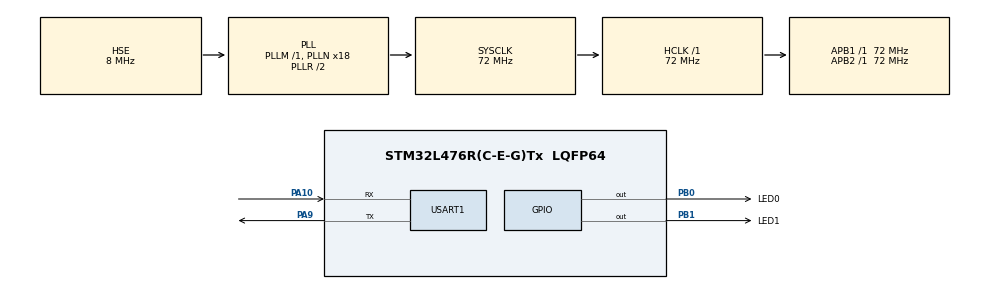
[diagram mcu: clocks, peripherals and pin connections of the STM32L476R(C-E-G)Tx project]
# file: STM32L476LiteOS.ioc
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Mcu.Family=STM32L4
Mcu.Name=STM32L476R(C-E-G)Tx
Mcu.Package=LQFP64
NVIC.PriorityGroup=NVIC_PRIORITYGROUP_4
PA10.Mode=Asynchronous
PA10.Signal=USART1_RX
PA9.Mode=Asynchronous
PA9.Signal=USART1_TX
PB0.GPIO_Label=LED0
PB0.Signal=GPIO_Output
PB1.GPIO_Label=LED1
PB1.Signal=GPIO_Output
PH0-OSC_IN\ (PH0).Mode=HSE-External-Oscillator
PH0-OSC_IN\ (PH0).Signal=RCC_OSC_IN
PH1-OSC_OUT\ (PH1).Mode=HSE-External-Oscillator
PH1-OSC_OUT\ (PH1).Signal=RCC_OSC_OUT
ProjectManager.HeapSize=0x3000
ProjectManager.StackSize=0x400
ProjectManager.TargetToolchain=MDK-ARM V5
RCC.ADCFreq_Value=32000000
RCC.AHBFreq_Value=72000000
RCC.APB1Freq_Value=72000000
RCC.APB1TimFreq_Value=72000000
RCC.APB2Freq_Value=72000000
RCC.APB2TimFreq_Value=72000000
RCC.CortexFreq_Value=72000000
RCC.HCLKFreq_Value=72000000
RCC.HSE_VALUE=8000000
RCC.HSI_VALUE=16000000
RCC.LSE_VALUE=32768
RCC.MSI_VALUE=4000000
RCC.PLLN=18
RCC.PLLSourceVirtual=RCC_PLLSOURCE_HSE
RCC.SYSCLKFreq_VALUE=72000000
RCC.SYSCLKSource=RCC_SYSCLKSOURCE_PLLCLK
RCC.USBFreq_Value=32000000
RCC.VCOOutputFreq_Value=144000000
USART1.VirtualMode-Asynchronous=VM_ASYNC
board=custom

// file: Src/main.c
/* USER CODE BEGIN Header */
/**
  ******************************************************************************
  * @file           : main.c
  * @brief          : Main program body
  ******************************************************************************
  ** This notice applies to any and all portions of this file
  * that are not between comment pairs USER CODE BEGIN and
  * USER CODE END. Other portions of this file, whether
  * inserted by the user or by software development tools
  * are owned by their respective copyright owners.
  *
  * COPYRIGHT(c) 2019 STMicroelectronics
  *
  * Redistribution and use in source and binary forms, with or without modification,
  * are permitted provided that the following conditions are met:
  *   1. Redistributions of source code must retain the above copyright notice,
  *      this list of conditions and the following disclaimer.
  *   2. Redistributions in binary form must reproduce the above copyright notice,
  *      this list of conditions and the following disclaimer in the documentation
  *      and/or other materials provided with the distribution.
  *   3. Neither the name of STMicroelectronics nor the names of its contributors
  *      may be used to endorse or promote products derived from this software
  *      without specific prior written permission.
  *
  * THIS SOFTWARE IS PROVIDED BY THE COPYRIGHT HOLDERS AND CONTRIBUTORS "AS IS"
  * AND ANY EXPRESS OR IMPLIED WARRANTIES, INCLUDING, BUT NOT LIMITED TO, THE
  * IMPLIED WARRANTIES OF MERCHANTABILITY AND FITNESS FOR A PARTICULAR PURPOSE ARE
  * DISCLAIMED. IN NO EVENT SHALL THE COPYRIGHT HOLDER OR CONTRIBUTORS BE LIABLE
  * FOR ANY DIRECT, INDIRECT, INCIDENTAL, SPECIAL, EXEMPLARY, OR CONSEQUENTIAL
  * DAMAGES (INCLUDING, BUT NOT LIMITED TO, PROCUREMENT OF SUBSTITUTE GOODS OR
  * SERVICES; LOSS OF USE, DATA, OR PROFITS; OR BUSINESS INTERRUPTION) HOWEVER
  * CAUSED AND ON ANY THEORY OF LIABILITY, WHETHER IN CONTRACT, STRICT LIABILITY,
  * OR TORT (INCLUDING NEGLIGENCE OR OTHERWISE) ARISING IN ANY WAY OUT OF THE USE
  * OF THIS SOFTWARE, EVEN IF ADVISED OF THE POSSIBILITY OF SUCH DAMAGE.
  *
  ******************************************************************************
  */
/* USER CODE END Header */

#include "main.h"
#include "usart.h"
#include "gpio.h"

/* USER CODE BEGIN Includes */
#include "los_base.h"

/* USER CODE END Includes */

void SystemClock_Config(void);

int main(void)
{

  /* MCU Configuration--------------------------------------------------------*/

  /* Reset of all peripherals, Initializes the Flash interface and the Systick. */
  HAL_Init();

  /* Configure the system clock */
  SystemClock_Config();

  /* Initialize all configured peripherals */
  MX_GPIO_Init();
  MX_USART1_UART_Init();
  /* USER CODE BEGIN 2 */
  if(LOS_OK != LOS_KernelInit())
  {
    return LOS_NOK;
  }
  LOS_Inspect_Entry();
  LOS_Start();

  /* USER CODE END 2 */

  /* Infinite loop */
  while (1)
  {

  }
}

void SystemClock_Config(void)
{
  RCC_OscInitTypeDef RCC_OscInitStruct = {0};
  RCC_ClkInitTypeDef RCC_ClkInitStruct = {0};
  RCC_PeriphCLKInitTypeDef PeriphClkInit = {0};

  /**Initializes the CPU, AHB and APB busses clocks
  */
  RCC_OscInitStruct.OscillatorType = RCC_OSCILLATORTYPE_HSE;
  RCC_OscInitStruct.HSEState = RCC_HSE_ON;
  RCC_OscInitStruct.PLL.PLLState = RCC_PLL_ON;
  RCC_OscInitStruct.PLL.PLLSource = RCC_PLLSOURCE_HSE;
  RCC_OscInitStruct.PLL.PLLM = 1;
  RCC_OscInitStruct.PLL.PLLN = 18;
  RCC_OscInitStruct.PLL.PLLP = RCC_PLLP_DIV7;
  RCC_OscInitStruct.PLL.PLLQ = RCC_PLLQ_DIV2;
  RCC_OscInitStruct.PLL.PLLR = RCC_PLLR_DIV2;
  if (HAL_RCC_OscConfig(&RCC_OscInitStruct) != HAL_OK)
  {
    Error_Handler();
  }
  /**Initializes the CPU, AHB and APB busses clocks
  */
  RCC_ClkInitStruct.ClockType = RCC_CLOCKTYPE_HCLK|RCC_CLOCKTYPE_SYSCLK
                              |RCC_CLOCKTYPE_PCLK1|RCC_CLOCKTYPE_PCLK2;
  RCC_ClkInitStruct.SYSCLKSource = RCC_SYSCLKSOURCE_PLLCLK;
  RCC_ClkInitStruct.AHBCLKDivider = RCC_SYSCLK_DIV1;
  RCC_ClkInitStruct.APB1CLKDivider = RCC_HCLK_DIV1;
  RCC_ClkInitStruct.APB2CLKDivider = RCC_HCLK_DIV1;

  if (HAL_RCC_ClockConfig(&RCC_ClkInitStruct, FLASH_LATENCY_4) != HAL_OK)
  {
    Error_Handler();
  }
  PeriphClkInit.PeriphClockSelection = RCC_PERIPHCLK_USART1;
  PeriphClkInit.Usart1ClockSelection = RCC_USART1CLKSOURCE_PCLK2;
  if (HAL_RCCEx_PeriphCLKConfig(&PeriphClkInit) != HAL_OK)
  {
    Error_Handler();
  }
  /**Configure the main internal regulator output voltage
  */
  if (HAL_PWREx_ControlVoltageScaling(PWR_REGULATOR_VOLTAGE_SCALE1) != HAL_OK)
  {
    Error_Handler();
  }
}

void Error_Handler(void)
{
}

/************************ (C) COPYRIGHT STMicroelectronics *****END OF FILE****/
